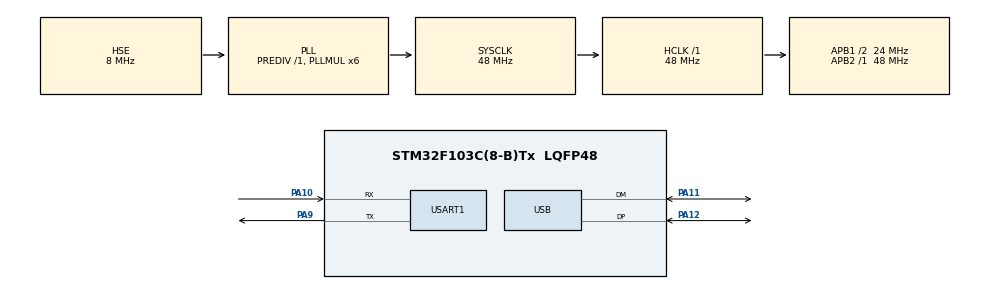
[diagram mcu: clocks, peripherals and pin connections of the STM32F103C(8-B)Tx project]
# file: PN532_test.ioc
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FREERTOS.Tasks01=defaultTask,24,128,StartDefaultTask,Default,NULL,Dynamic,NULL,NULL;PN532Task,10,192,Start_PN532_Task,As external,NULL,Dynamic,NULL,NULL;PN532_test_Task,24,128,StartPN532_tsstTask,As external,NULL,Dynamic,NULL,NULL;KeyBoardTask,40,128,StartKeyBoardTask,As external,NULL,Dynamic,NULL,NULL
FREERTOS.configGENERATE_RUN_TIME_STATS=1
FREERTOS.configRECORD_STACK_HIGH_ADDRESS=1
FREERTOS.configTOTAL_HEAP_SIZE=6114
FREERTOS.configUSE_NEWLIB_REENTRANT=0
Mcu.Family=STM32F1
Mcu.Name=STM32F103C(8-B)Tx
Mcu.Package=LQFP48
NVIC.PriorityGroup=NVIC_PRIORITYGROUP_4
NVIC.USART1_IRQn=true\:6\:0\:true\:false\:true\:true\:true\:true\:true
NVIC.USB_LP_CAN1_RX0_IRQn=true\:5\:0\:false\:false\:true\:true\:true\:true\:true
PA10.Mode=Asynchronous
PA10.Signal=USART1_RX
PA11.Mode=Device
PA11.Signal=USB_DM
PA12.Mode=Device
PA12.Signal=USB_DP
PA13.Mode=JTAG_4_pins
PA13.Signal=SYS_JTMS-SWDIO
PA14.Mode=JTAG_4_pins
PA14.Signal=SYS_JTCK-SWCLK
PA15.Mode=JTAG_4_pins
PA15.Signal=SYS_JTDI
PA9.Mode=Asynchronous
PA9.Signal=USART1_TX
PB3.Mode=JTAG_4_pins
PB3.Signal=SYS_JTDO-TRACESWO
PD0-OSC_IN.Mode=HSE-External-Oscillator
PD0-OSC_IN.Signal=RCC_OSC_IN
PD1-OSC_OUT.Mode=HSE-External-Oscillator
PD1-OSC_OUT.Signal=RCC_OSC_OUT
ProjectManager.HeapSize=0x200
ProjectManager.StackSize=0x400
ProjectManager.TargetToolchain=CMake
RCC.AHBFreq_Value=48000000
RCC.APB1CLKDivider=RCC_HCLK_DIV2
RCC.APB1Freq_Value=24000000
RCC.APB1TimFreq_Value=48000000
RCC.APB2Freq_Value=48000000
RCC.APB2TimFreq_Value=48000000
RCC.HCLKFreq_Value=48000000
RCC.PLLMUL=RCC_PLL_MUL6
RCC.PLLSourceVirtual=RCC_PLLSOURCE_HSE
RCC.SYSCLKFreq_VALUE=48000000
RCC.SYSCLKSource=RCC_SYSCLKSOURCE_PLLCLK
RCC.USBFreq_Value=48000000
RealThread.X-CUBE-RT-Thread_Nano.4.1.1.RT_DEBUG=1
RealThread.X-CUBE-RT-Thread_Nano.4.1.1.RT_DEBUG_INIT=1
RealThread.X-CUBE-RT-Thread_Nano.4.1.1.RT_USING_OVERFLOW_CHECK=1
RealThread.X-CUBE-RT-Thread_Nano.4.1.1.RT_USING_TIMER_SOFT=1
USART1.VirtualMode=VM_ASYNC
VP_FREERTOS_VS_CMSIS_V2.Mode=CMSIS_V2
board=custom

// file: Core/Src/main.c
/* USER CODE BEGIN Header */
/**
 ******************************************************************************
 * @file           : main.c
 * @brief          : Main program body
 ******************************************************************************
 * @attention
 *
 * Copyright (c) 2025 STMicroelectronics.
 * All rights reserved.
 *
 * This software is licensed under terms that can be found in the LICENSE file
 * in the root directory of this software component.
 * If no LICENSE file comes with this software, it is provided AS-IS.
 *
 ******************************************************************************
 */
/* USER CODE END Header */
#include "main.h"
#include "cmsis_os.h"

PCD_HandleTypeDef hpcd_USB_FS;

/* Definitions for defaultTask */
osThreadId_t defaultTaskHandle;
const osThreadAttr_t defaultTask_attributes = {
  .name = "defaultTask",
  .stack_size = 128 * 4,
  .priority = (osPriority_t) osPriorityNormal,
};
/* Definitions for PN532Task */
osThreadId_t PN532TaskHandle;
const osThreadAttr_t PN532Task_attributes = {
  .name = "PN532Task",
  .stack_size = 192 * 4,
  .priority = (osPriority_t) osPriorityLow2,
};
/* Definitions for PN532_test_Task */
osThreadId_t PN532_test_TaskHandle;
const osThreadAttr_t PN532_test_Task_attributes = {
  .name = "PN532_test_Task",
  .stack_size = 128 * 4,
  .priority = (osPriority_t) osPriorityNormal,
};
/* Definitions for KeyBoardTask */
osThreadId_t KeyBoardTaskHandle;
const osThreadAttr_t KeyBoardTask_attributes = {
  .name = "KeyBoardTask",
  .stack_size = 128 * 4,
  .priority = (osPriority_t) osPriorityHigh,
};

void SystemClock_Config(void);
static void MX_GPIO_Init(void);
static void MX_USART1_UART_Init(void);
static void MX_USB_PCD_Init(void);
void StartDefaultTask(void *argument);
extern void Start_PN532_Task(void *argument);
extern void StartPN532_tsstTask(void *argument);
extern void StartKeyBoardTask(void *argument);

int main(void)
{

  /* MCU Configuration--------------------------------------------------------*/

  /* Reset of all peripherals, Initializes the Flash interface and the Systick. */
  HAL_Init();

  /* Configure the system clock */
  SystemClock_Config();

  /* Initialize all configured peripherals */
  MX_GPIO_Init();
  MX_USART1_UART_Init();
  // MX_USB_PCD_Init();
  /* USER CODE BEGIN 2 */
	LL_USART_EnableIT_RXNE(USART1);
	extern void hid_keyboard_init(uint8_t busid, uint32_t reg_base);
	hid_keyboard_init(0, USB_BASE);
  /* USER CODE END 2 */

  /* Init scheduler */
  osKernelInitialize();

  /* USER CODE BEGIN RTOS_MUTEX */
	// /* add mutexes, ... */
  /* USER CODE END RTOS_MUTEX */

  /* USER CODE BEGIN RTOS_SEMAPHORES */
	// /* add semaphores, ... */
  /* USER CODE END RTOS_SEMAPHORES */

  /* USER CODE BEGIN RTOS_TIMERS */
	// /* start timers, add new ones, ... */
  /* USER CODE END RTOS_TIMERS */

  /* USER CODE BEGIN RTOS_QUEUES */
	// /* add queues, ... */
  /* USER CODE END RTOS_QUEUES */

  /* Create the thread(s) */
  /* creation of defaultTask */
  defaultTaskHandle = osThreadNew(StartDefaultTask, NULL, &defaultTask_attributes);

  /* creation of PN532Task */
  PN532TaskHandle = osThreadNew(Start_PN532_Task, NULL, &PN532Task_attributes);

  /* creation of PN532_test_Task */
  PN532_test_TaskHandle = osThreadNew(StartPN532_tsstTask, NULL, &PN532_test_Task_attributes);

  /* creation of KeyBoardTask */
  KeyBoardTaskHandle = osThreadNew(StartKeyBoardTask, NULL, &KeyBoardTask_attributes);

  /* Start scheduler */
  osKernelStart();

  /* We should never get here as control is now taken by the scheduler */

  /* Infinite loop */
	while (1)
	{

	}
}

void SystemClock_Config(void)
{
  RCC_OscInitTypeDef RCC_OscInitStruct = {0};
  RCC_ClkInitTypeDef RCC_ClkInitStruct = {0};
  RCC_PeriphCLKInitTypeDef PeriphClkInit = {0};

  /** Initializes the RCC Oscillators according to the specified parameters
  * in the RCC_OscInitTypeDef structure.
  */
  RCC_OscInitStruct.OscillatorType = RCC_OSCILLATORTYPE_HSE;
  RCC_OscInitStruct.HSEState = RCC_HSE_ON;
  RCC_OscInitStruct.HSEPredivValue = RCC_HSE_PREDIV_DIV1;
  RCC_OscInitStruct.HSIState = RCC_HSI_ON;
  RCC_OscInitStruct.PLL.PLLState = RCC_PLL_ON;
  RCC_OscInitStruct.PLL.PLLSource = RCC_PLLSOURCE_HSE;
  RCC_OscInitStruct.PLL.PLLMUL = RCC_PLL_MUL6;
  if (HAL_RCC_OscConfig(&RCC_OscInitStruct) != HAL_OK)
  {
    Error_Handler();
  }

  /** Initializes the CPU, AHB and APB buses clocks
  */
  RCC_ClkInitStruct.ClockType = RCC_CLOCKTYPE_HCLK|RCC_CLOCKTYPE_SYSCLK
                              |RCC_CLOCKTYPE_PCLK1|RCC_CLOCKTYPE_PCLK2;
  RCC_ClkInitStruct.SYSCLKSource = RCC_SYSCLKSOURCE_PLLCLK;
  RCC_ClkInitStruct.AHBCLKDivider = RCC_SYSCLK_DIV1;
  RCC_ClkInitStruct.APB1CLKDivider = RCC_HCLK_DIV2;
  RCC_ClkInitStruct.APB2CLKDivider = RCC_HCLK_DIV1;

  if (HAL_RCC_ClockConfig(&RCC_ClkInitStruct, FLASH_LATENCY_1) != HAL_OK)
  {
    Error_Handler();
  }
  PeriphClkInit.PeriphClockSelection = RCC_PERIPHCLK_USB;
  PeriphClkInit.UsbClockSelection = RCC_USBCLKSOURCE_PLL;
  if (HAL_RCCEx_PeriphCLKConfig(&PeriphClkInit) != HAL_OK)
  {
    Error_Handler();
  }
}

static void MX_USART1_UART_Init(void)
{

  LL_USART_InitTypeDef USART_InitStruct = {0};

  LL_GPIO_InitTypeDef GPIO_InitStruct = {0};

  /* Peripheral clock enable */
  LL_APB2_GRP1_EnableClock(LL_APB2_GRP1_PERIPH_USART1);

  LL_APB2_GRP1_EnableClock(LL_APB2_GRP1_PERIPH_GPIOA);
  /**USART1 GPIO Configuration
  PA9   ------> USART1_TX
  PA10   ------> USART1_RX
  */
  GPIO_InitStruct.Pin = LL_GPIO_PIN_9;
  GPIO_InitStruct.Mode = LL_GPIO_MODE_ALTERNATE;
  GPIO_InitStruct.Speed = LL_GPIO_SPEED_FREQ_HIGH;
  GPIO_InitStruct.OutputType = LL_GPIO_OUTPUT_PUSHPULL;
  LL_GPIO_Init(GPIOA, &GPIO_InitStruct);

  GPIO_InitStruct.Pin = LL_GPIO_PIN_10;
  GPIO_InitStruct.Mode = LL_GPIO_MODE_FLOATING;
  LL_GPIO_Init(GPIOA, &GPIO_InitStruct);

  /* USART1 interrupt Init */
  NVIC_SetPriority(USART1_IRQn, NVIC_EncodePriority(NVIC_GetPriorityGrouping(),6, 0));
  NVIC_EnableIRQ(USART1_IRQn);

  USART_InitStruct.BaudRate = 115200;
  USART_InitStruct.DataWidth = LL_USART_DATAWIDTH_8B;
  USART_InitStruct.StopBits = LL_USART_STOPBITS_1;
  USART_InitStruct.Parity = LL_USART_PARITY_NONE;
  USART_InitStruct.TransferDirection = LL_USART_DIRECTION_TX_RX;
  USART_InitStruct.HardwareFlowControl = LL_USART_HWCONTROL_NONE;
  USART_InitStruct.OverSampling = LL_USART_OVERSAMPLING_16;
  LL_USART_Init(USART1, &USART_InitStruct);
  LL_USART_ConfigAsyncMode(USART1);
  LL_USART_Enable(USART1);

}

static void MX_USB_PCD_Init(void)
{

  hpcd_USB_FS.Instance = USB;
  hpcd_USB_FS.Init.dev_endpoints = 8;
  hpcd_USB_FS.Init.speed = PCD_SPEED_FULL;
  hpcd_USB_FS.Init.low_power_enable = DISABLE;
  hpcd_USB_FS.Init.lpm_enable = DISABLE;
  hpcd_USB_FS.Init.battery_charging_enable = DISABLE;
  if (HAL_PCD_Init(&hpcd_USB_FS) != HAL_OK)
  {
    Error_Handler();
  }

}

static void MX_GPIO_Init(void)
{

  /* GPIO Ports Clock Enable */
  __HAL_RCC_GPIOD_CLK_ENABLE();
  __HAL_RCC_GPIOA_CLK_ENABLE();
  __HAL_RCC_GPIOB_CLK_ENABLE();

}

void StartDefaultTask(void *argument)
{
  /* USER CODE BEGIN 5 */
	(void)argument;
	/* Infinite loop */
	for (;;)
	{
		osDelay(1);
	}
  /* USER CODE END 5 */
}

void Error_Handler(void)
{
	__disable_irq();
	while (1)
	{
	}
}
